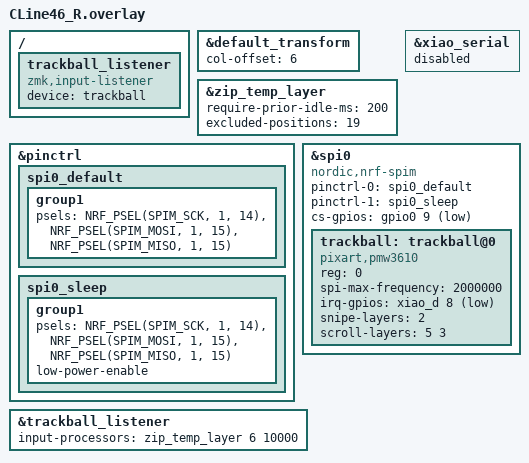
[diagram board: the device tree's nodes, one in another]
#include "CLine46.dtsi"
#include <input/processors.dtsi>
#include <behaviors/battery_history_request.dtsi>

&default_transform {
    col-offset = <6>;
};

// AML(オートマウスレイヤー)挙動 ─ LiNEA40 を参考
&zip_temp_layer {
    require-prior-idle-ms = <200>;

    excluded-positions = <
        19 // J
    >;
};


/ {
    trackball_listener {
        status = "okay";
        compatible = "zmk,input-listener";
        device = <&trackball>;
    };
};

&pinctrl {
    spi0_default: spi0_default {
        group1 {
            psels = <NRF_PSEL(SPIM_SCK, 1, 14)>,
                <NRF_PSEL(SPIM_MOSI, 1, 15)>,
                <NRF_PSEL(SPIM_MISO, 1, 15)>;
        };
    };

    spi0_sleep: spi0_sleep {
        group1 {
            psels = <NRF_PSEL(SPIM_SCK, 1, 14)>,
                <NRF_PSEL(SPIM_MOSI, 1, 15)>,
                <NRF_PSEL(SPIM_MISO, 1, 15)>;
            low-power-enable;
        };
    };
};


&xiao_serial { status = "disabled"; };

&spi0 {
    status = "okay";
    compatible = "nordic,nrf-spim";
    pinctrl-0 = <&spi0_default>;
    pinctrl-1 = <&spi0_sleep>;
    pinctrl-names = "default", "sleep";
    cs-gpios = <&gpio0 9 GPIO_ACTIVE_LOW>;

    trackball: trackball@0 {
        status = "okay";
        compatible = "pixart,pmw3610";
        reg = <0>;
        spi-max-frequency = <2000000>;
        irq-gpios = <&xiao_d 8 (GPIO_ACTIVE_LOW | GPIO_PULL_UP)>;

        // LiNEA40 方式: スナイプ/スクロールをドライバ側で処理
        snipe-layers = <2>;
        scroll-layers = <5 3>;
    };
};

&trackball_listener {
    status = "okay";
    input-processors = <&zip_temp_layer 6 10000>;
};
